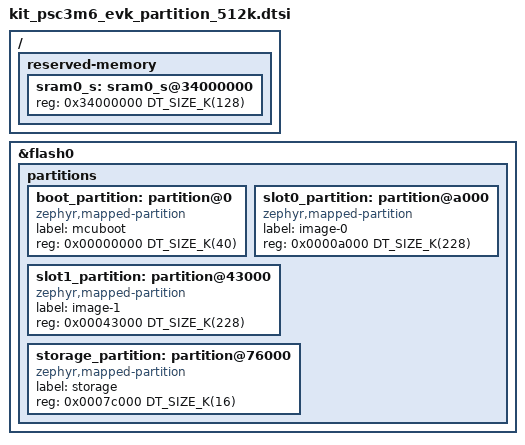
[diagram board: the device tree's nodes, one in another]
/*
 * SPDX-FileCopyrightText: Copyright (c) 2026 Infineon Technologies AG,
 * SPDX-FileCopyrightText: or an affiliate of Infineon Technologies AG. All rights reserved.
 *
 * SPDX-License-Identifier: Apache-2.0
 */

/*
 * 40 KB mcuboot, two 228 KB image slots, and 16 KB storage partition (512 KB total).
 * Valid only for the 512 KB-flash PSC3M6 MPNs (psc3m6ges3a*q1). The 256 KB MPNs
 * (psc3m6fds2a*q1) must use kit_psc3m6_evk_partition_256k.dtsi instead.
 */
/ {
	reserved-memory {
		#address-cells = <1>;
		#size-cells = <1>;
		ranges;

		sram0_s: sram0_s@34000000 {
			/* Secure image SRAM */
			reg = <0x34000000 DT_SIZE_K(128)>;
		};
	};
};

&flash0 {
	partitions {
		ranges;
		#address-cells = <1>;
		#size-cells = <1>;

		boot_partition: partition@0 {
			compatible = "zephyr,mapped-partition";
			label = "mcuboot";
			reg = <0x00000000 DT_SIZE_K(40)>;
		};

		slot0_partition: partition@a000 {
			compatible = "zephyr,mapped-partition";
			label = "image-0";
			reg = <0x0000a000 DT_SIZE_K(228)>;
		};

		slot1_partition: partition@43000 {
			compatible = "zephyr,mapped-partition";
			label = "image-1";
			reg = <0x00043000 DT_SIZE_K(228)>;
		};

		storage_partition: partition@76000 {
			compatible = "zephyr,mapped-partition";
			label = "storage";
			reg = <0x0007c000 DT_SIZE_K(16)>;
		};
	};
};
